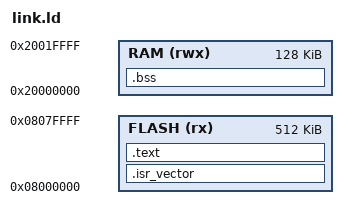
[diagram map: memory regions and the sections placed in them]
MEMORY {
  FLASH (rx) : ORIGIN = 0x08000000, LENGTH = 512K
  RAM  (rwx) : ORIGIN = 0x20000000, LENGTH = 128K
}
_estack = ORIGIN(RAM) + LENGTH(RAM);
ENTRY(Reset_Handler)
SECTIONS {
  .isr_vector : { KEEP(*(.isr_vector)) } > FLASH
  .text : { *(.text*) *(.rodata*) } > FLASH
  .bss  : { _sbss = .; *(.bss*) *(COMMON) _ebss = .; } > RAM
  /DISCARD/ : { *(.ARM.exidx*) *(.ARM.extab*) *(.comment) }
}
